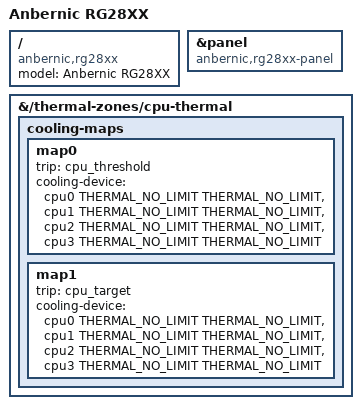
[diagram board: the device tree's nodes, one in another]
// SPDX-License-Identifier: (GPL-2.0-only OR BSD-2-Clause)
/*
 * Anbernic RG28XX device tree overlay on the (ROCKNIX-patched) mainline
 * rg35xx-plus base. The &panel reference resolves because ROCKNIX
 * patches 0111/0126 add spi-gpio + panel + backlight nodes to the
 * rg35xx-2024 base DTS — we just override the panel compatible to load
 * the rg28xx-specific firmware blob.
 *
 * Copyright (C) 2024 Ryan Walklin <ryan@testtoast.com>.
 * Copyright (C) 2024 Chris Morgan <macroalpha82@gmail.com>.
 */

#include "sun50i-h700-anbernic-rg35xx-plus.dts"

/ {
	model = "Anbernic RG28XX";
	compatible = "anbernic,rg28xx", "allwinner,sun50i-h700";
};

&panel {
	compatible = "anbernic,rg28xx-panel", "panel-mipi-dpi-spi";
};

/*
 * sun50i-h616.dtsi declares the cpu-thermal trips but binds no cooling
 * device to them, so the passive trips are inert and the only thermal
 * response is the 110C critical shutdown. cpufreq-dt registers a
 * cpufreq-cpu0 cooling device; map it onto both passive trips so the
 * step_wise governor can actually throttle. Mirrors the sun50i-h6.dtsi
 * pattern. All four CPUs share one OPP table (opp-shared).
 */
&{/thermal-zones/cpu-thermal} {
	cooling-maps {
		map0 {
			trip = <&cpu_threshold>;
			cooling-device = <&cpu0 THERMAL_NO_LIMIT THERMAL_NO_LIMIT>,
					 <&cpu1 THERMAL_NO_LIMIT THERMAL_NO_LIMIT>,
					 <&cpu2 THERMAL_NO_LIMIT THERMAL_NO_LIMIT>,
					 <&cpu3 THERMAL_NO_LIMIT THERMAL_NO_LIMIT>;
		};

		map1 {
			trip = <&cpu_target>;
			cooling-device = <&cpu0 THERMAL_NO_LIMIT THERMAL_NO_LIMIT>,
					 <&cpu1 THERMAL_NO_LIMIT THERMAL_NO_LIMIT>,
					 <&cpu2 THERMAL_NO_LIMIT THERMAL_NO_LIMIT>,
					 <&cpu3 THERMAL_NO_LIMIT THERMAL_NO_LIMIT>;
		};
	};
};
